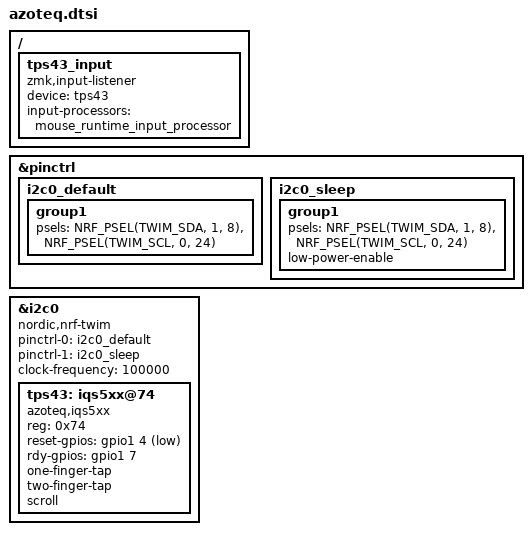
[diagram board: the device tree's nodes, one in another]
/*
 * Azoteq TPS43 (IQS5xx) trackpad (I2C) on the right (central) half.
 *
 * Pins: SDA = P1.08, SCL = P0.24, RST = P1.04 (active-low),
 *       RDY = P1.07 (active-high).
 */

#include <zephyr/dt-bindings/input/input-event-codes.h>
#include <input/processors/runtime-input-processor.dtsi>

&pinctrl {
    i2c0_default: i2c0_default {
        group1 {
            psels = <NRF_PSEL(TWIM_SDA, 1, 8)>,
                    <NRF_PSEL(TWIM_SCL, 0, 24)>;
        };
    };

    i2c0_sleep: i2c0_sleep {
        group1 {
            psels = <NRF_PSEL(TWIM_SDA, 1, 8)>,
                    <NRF_PSEL(TWIM_SCL, 0, 24)>;
            low-power-enable;
        };
    };
};

&i2c0 {
    status = "okay";
    compatible = "nordic,nrf-twim";
    pinctrl-0 = <&i2c0_default>;
    pinctrl-1 = <&i2c0_sleep>;
    pinctrl-names = "default", "sleep";
    clock-frequency = <100000>;

    tps43: iqs5xx@74 {
        compatible = "azoteq,iqs5xx";
        reg = <0x74>;
        status = "okay";
        reset-gpios = <&gpio1 4 GPIO_ACTIVE_LOW>;
        rdy-gpios = <&gpio1 7 GPIO_ACTIVE_HIGH>;
        one-finger-tap;
        two-finger-tap;
        scroll;
    };
};

/ {
    /*
     * Runtime input processor: what DYA Studio's Trackpad page drives from its
     * "Runtime pointer speed" card (the card only appears when this subsystem
     * is in the firmware). Without a processor in the listener chain, pointer
     * speed has nothing to act on and every position feels identical.
     * `mouse_runtime_input_processor` is the module's zero-cell default
     * (scale 1/1); speed and rotation are then tunable at runtime. Wheel
     * events from the driver pass through untouched: they are not one of this
     * processor's X/Y codes, and attaching the module's 1/60 scroll processor
     * here would divide already-scaled wheel steps into nothing.
     */
    tps43_input: tps43_input {
        compatible = "zmk,input-listener";
        device = <&tps43>;
        input-processors = <&mouse_runtime_input_processor>;
    };
};
